VERSION ""

NS_ :

BS_:

BU_: MMU ICM BCM
VAL_TABLE_ MMU_Value 0 "Default" ;
VAL_TABLE_ BCM_Value 4094 "Fault/Error" 0 "Default" ;
VAL_TABLE_ ICM_Value 3 "Reserve" 2 "Blinking" 1 "Low Fuel" 0 "Normal" ;

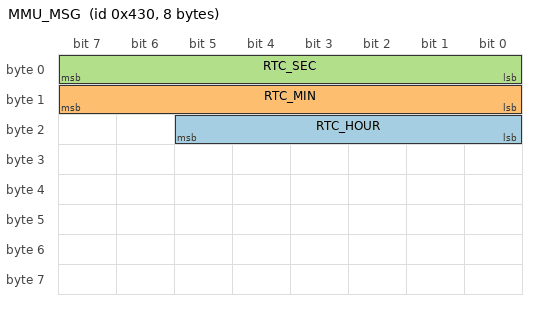
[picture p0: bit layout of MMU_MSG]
BO_ 1072 MMU_MSG: 8 MMU
 SG_ RTC_HOUR : 16|6@1- (1,0) [0|0] ""  ICM
 SG_ RTC_MIN : 8|8@1- (1,0) [0|0] ""  ICM
 SG_ RTC_SEC : 0|8@1- (1,0) [0|0] ""  ICM

BO_ 544 ICM_MSG: 8 ICM
 SG_ LOW_FUEL_LMP_STTS : 6|2@1+ (1,0) [0|0] ""  MMU

BO_ 257 EMS_MSG_1: 8 BCM
 SG_ VEH_SPD : 0|12@1- (0.125,0) [0|511.625] "Km/h"  MMU,ICM

BA_DEF_ BO_  "GenMsgCycleTime" INT 0 1000;
BA_DEF_DEF_  "GenMsgCycleTime" 0;
BA_ "GenMsgCycleTime" BO_ 1072 1000;
BA_ "GenMsgCycleTime" BO_ 544 100;
BA_ "GenMsgCycleTime" BO_ 257 100;
VAL_ 1072 RTC_HOUR 0 "Default" ;
VAL_ 1072 RTC_MIN 0 "Default" ;
VAL_ 1072 RTC_SEC 0 "Default" ;
VAL_ 544 LOW_FUEL_LMP_STTS 3 "Reserve" 2 "Blinking" 1 "Low Fuel" 0 "Normal" ;
VAL_ 257 VEH_SPD 4094 "Fault/Error" 0 "Default" ;
